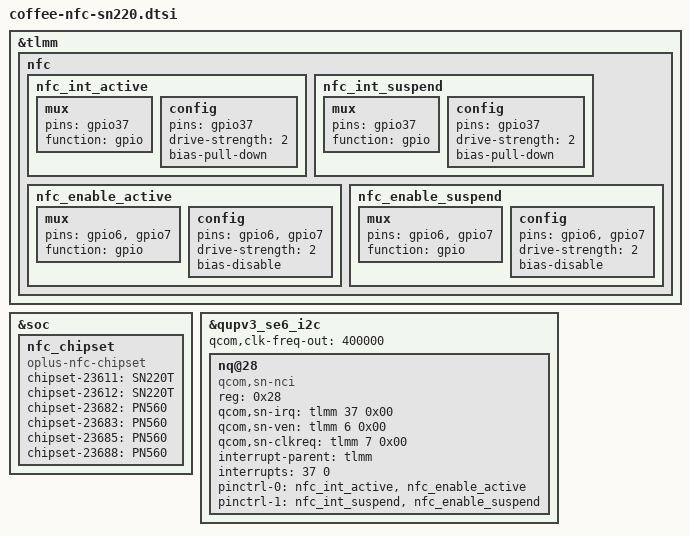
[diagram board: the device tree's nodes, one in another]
/**********************************************************************************
* Copyright (c)  2008-2020  Guangdong oplus Mobile Comm Corp., Ltd
* Description: oplus sn110t nfc dtsi
*
***********************************************************************************/
&tlmm {

    nfc {
        nfc_int_active: nfc_int_active {
            /* active state */
            mux {
                /* NFC Read Interrupt */
                pins = "gpio37";
                function = "gpio";
            };

            config {
                pins = "gpio37";
                drive-strength = <2>; /* 2 MA */
                bias-pull-down;
            };
        };

        nfc_int_suspend: nfc_int_suspend {
            /* sleep state */
            mux {
                /* NFC Read Interrupt */
                pins = "gpio37";
                function = "gpio";
            };

            config {
                pins = "gpio37";
                drive-strength = <2>; /* 2 MA */
                bias-pull-down;
            };
        };

        nfc_enable_active: nfc_enable_active {
            mux {
                /* Enable, Clock request gpios */
                pins = "gpio6", "gpio7";
                function = "gpio";
            };

            config {
                pins = "gpio6", "gpio7";
                drive-strength = <2>; /* 2 MA */
                bias-disable;
            };
        };

        nfc_enable_suspend: nfc_enable_suspend {
            mux {
                pins = "gpio6", "gpio7";
                function = "gpio";
            };

            config {
                pins = "gpio6", "gpio7";
                drive-strength = <2>; /* 2 MA */
                bias-disable;
            };
        };
    };
};

&soc {
    //add for nfc_chipset
    nfc_chipset {
        compatible = "oplus-nfc-chipset";
        chipset-23611 = "SN220T";// coffee china
	chipset-23612 = "SN220T";// coffeeA china
	chipset-23682 = "PN560";// coffee india
	chipset-23683 = "PN560";// coffee global
	chipset-23685 = "PN560";// coffeeA global
	chipset-23688 = "PN560";// coffeeN india
    };
};

&qupv3_se6_i2c {
        status = "ok";
        qcom,clk-freq-out = <400000>;
        #address-cells = <1>;
        #size-cells = <0>;
        nq@28 {
                compatible = "qcom,sn-nci";
                reg = <0x28>;
                qcom,sn-irq = <&tlmm 37 0x00>;
                qcom,sn-ven = <&tlmm 6 0x00>;
                qcom,sn-clkreq = <&tlmm 7 0x00>;
                interrupt-parent = <&tlmm>;
                interrupts = <37 0>;
                interrupt-names = "nfc_irq";
                pinctrl-names = "nfc_active", "nfc_suspend";
                pinctrl-0 = <&nfc_int_active &nfc_enable_active>;
                pinctrl-1 = <&nfc_int_suspend &nfc_enable_suspend>;
        };
};

